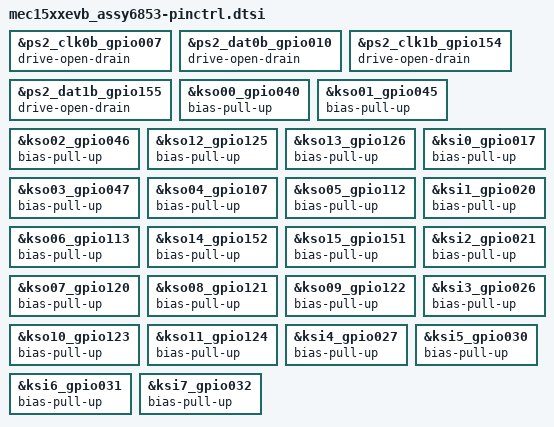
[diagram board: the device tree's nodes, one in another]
/*
 * Copyright (c) 2022, Microchip Technology Inc.
 *
 * SPDX-License-Identifier: Apache-2.0
 */

/dts-v1/;

#include <microchip/mec1501hsz.dtsi>
#include <microchip/mec152x/mec152xhsz-pinctrl.dtsi>

&ps2_clk0b_gpio007 {
	drive-open-drain;
};

&ps2_dat0b_gpio010 {
	drive-open-drain;
};

&ps2_clk1b_gpio154 {
	drive-open-drain;
};

&ps2_dat1b_gpio155 {
	drive-open-drain;
};

&kso00_gpio040 {
	bias-pull-up;
};

&kso01_gpio045 {
	bias-pull-up;
};

&kso02_gpio046 {
	bias-pull-up;
};

&kso12_gpio125 {
	bias-pull-up;
};

&kso13_gpio126 {
	bias-pull-up;
};

&kso03_gpio047 {
	bias-pull-up;
};

&kso04_gpio107 {
	bias-pull-up;
};

&kso05_gpio112 {
	bias-pull-up;
};

&kso06_gpio113 {
	bias-pull-up;
};

&kso14_gpio152 {
	bias-pull-up;
};

&kso15_gpio151 {
	bias-pull-up;
};

&kso07_gpio120 {
	bias-pull-up;
};

&kso08_gpio121 {
	bias-pull-up;
};

&kso09_gpio122 {
	bias-pull-up;
};

&kso10_gpio123 {
	bias-pull-up;
};

&kso11_gpio124 {
	bias-pull-up;
};

&ksi0_gpio017 {
	bias-pull-up;
};

&ksi1_gpio020 {
	bias-pull-up;
};

&ksi2_gpio021 {
	bias-pull-up;
};

&ksi3_gpio026 {
	bias-pull-up;
};

&ksi4_gpio027 {
	bias-pull-up;
};

&ksi5_gpio030 {
	bias-pull-up;
};

&ksi6_gpio031 {
	bias-pull-up;
};

&ksi7_gpio032 {
	bias-pull-up;
};
